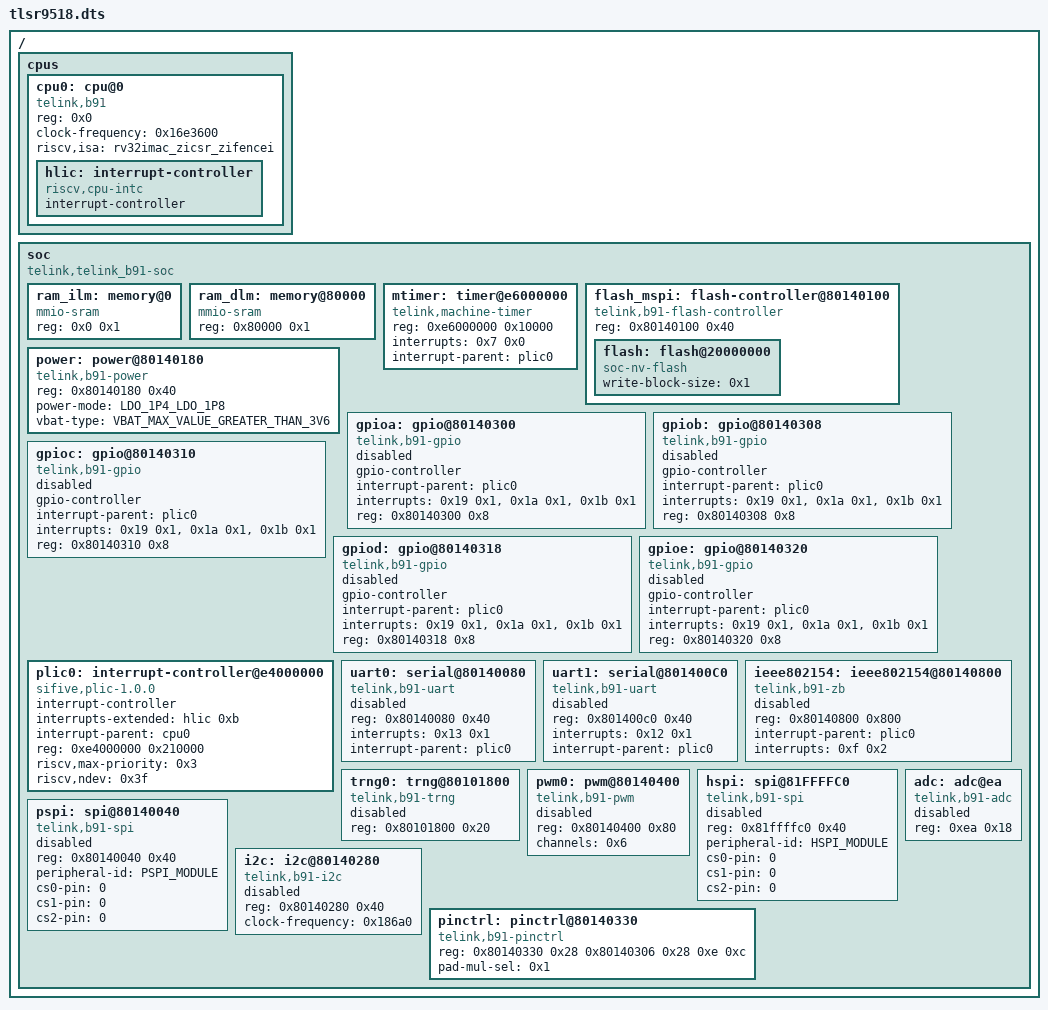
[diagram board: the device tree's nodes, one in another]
/dts-v1/;

/ {
	#address-cells = < 0x1 >;
	#size-cells = < 0x1 >;
	cpus {
		#address-cells = < 0x1 >;
		#size-cells = < 0x0 >;
		cpu0: cpu@0 {
			reg = < 0x0 >;
			clock-frequency = < 0x16e3600 >;
			compatible = "telink,b91", "riscv";
			riscv,isa = "rv32imac_zicsr_zifencei";
			phandle = < 0x3 >;
			hlic: interrupt-controller {
				compatible = "riscv,cpu-intc";
				#address-cells = < 0x0 >;
				#interrupt-cells = < 0x1 >;
				interrupt-controller;
				phandle = < 0x2 >;
			};
		};
	};
	soc {
		#address-cells = < 0x1 >;
		#size-cells = < 0x1 >;
		compatible = "telink,telink_b91-soc";
		ranges;
		ram_ilm: memory@0 {
			compatible = "mmio-sram";
			reg = < 0x0 0x1 >;
		};
		ram_dlm: memory@80000 {
			compatible = "mmio-sram";
			reg = < 0x80000 0x1 >;
		};
		mtimer: timer@e6000000 {
			compatible = "telink,machine-timer";
			reg = < 0xe6000000 0x10000 >;
			interrupts = < 0x7 0x0 >;
			interrupt-parent = < &plic0 >;
		};
		flash_mspi: flash-controller@80140100 {
			compatible = "telink,b91-flash-controller";
			reg = < 0x80140100 0x40 >;
			#address-cells = < 0x1 >;
			#size-cells = < 0x1 >;
			flash: flash@20000000 {
				compatible = "soc-nv-flash";
				write-block-size = < 0x1 >;
			};
		};
		power: power@80140180 {
			compatible = "telink,b91-power";
			reg = < 0x80140180 0x40 >;
			power-mode = "LDO_1P4_LDO_1P8";
			vbat-type = "VBAT_MAX_VALUE_GREATER_THAN_3V6";
			status = "okay";
		};
		gpioa: gpio@80140300 {
			compatible = "telink,b91-gpio";
			gpio-controller;
			interrupt-parent = < &plic0 >;
			interrupts = < 0x19 0x1 >, < 0x1a 0x1 >, < 0x1b 0x1 >;
			reg = < 0x80140300 0x8 >;
			status = "disabled";
			#gpio-cells = < 0x2 >;
		};
		gpiob: gpio@80140308 {
			compatible = "telink,b91-gpio";
			gpio-controller;
			interrupt-parent = < &plic0 >;
			interrupts = < 0x19 0x1 >, < 0x1a 0x1 >, < 0x1b 0x1 >;
			reg = < 0x80140308 0x8 >;
			status = "disabled";
			#gpio-cells = < 0x2 >;
		};
		gpioc: gpio@80140310 {
			compatible = "telink,b91-gpio";
			gpio-controller;
			interrupt-parent = < &plic0 >;
			interrupts = < 0x19 0x1 >, < 0x1a 0x1 >, < 0x1b 0x1 >;
			reg = < 0x80140310 0x8 >;
			status = "disabled";
			#gpio-cells = < 0x2 >;
		};
		gpiod: gpio@80140318 {
			compatible = "telink,b91-gpio";
			gpio-controller;
			interrupt-parent = < &plic0 >;
			interrupts = < 0x19 0x1 >, < 0x1a 0x1 >, < 0x1b 0x1 >;
			reg = < 0x80140318 0x8 >;
			status = "disabled";
			#gpio-cells = < 0x2 >;
		};
		gpioe: gpio@80140320 {
			compatible = "telink,b91-gpio";
			gpio-controller;
			interrupt-parent = < &plic0 >;
			interrupts = < 0x19 0x1 >, < 0x1a 0x1 >, < 0x1b 0x1 >;
			reg = < 0x80140320 0x8 >;
			status = "disabled";
			#gpio-cells = < 0x2 >;
		};
		plic0: interrupt-controller@e4000000 {
			compatible = "sifive,plic-1.0.0";
			#address-cells = < 0x0 >;
			#interrupt-cells = < 0x2 >;
			interrupt-controller;
			interrupts-extended = < &hlic 0xb >;
			interrupt-parent = < &cpu0 >;
			reg = < 0xe4000000 0x210000 >;
			riscv,max-priority = < 0x3 >;
			riscv,ndev = < 0x3f >;
			phandle = < 0x1 >;
		};
		uart0: serial@80140080 {
			compatible = "telink,b91-uart";
			reg = < 0x80140080 0x40 >;
			interrupts = < 0x13 0x1 >;
			interrupt-parent = < &plic0 >;
			status = "disabled";
		};
		uart1: serial@801400C0 {
			compatible = "telink,b91-uart";
			reg = < 0x801400c0 0x40 >;
			interrupts = < 0x12 0x1 >;
			interrupt-parent = < &plic0 >;
			status = "disabled";
		};
		ieee802154: ieee802154@80140800 {
			compatible = "telink,b91-zb";
			reg = < 0x80140800 0x800 >;
			interrupt-parent = < &plic0 >;
			interrupts = < 0xf 0x2 >;
			status = "disabled";
		};
		trng0: trng@80101800 {
			compatible = "telink,b91-trng";
			reg = < 0x80101800 0x20 >;
			status = "disabled";
		};
		pwm0: pwm@80140400 {
			compatible = "telink,b91-pwm";
			reg = < 0x80140400 0x80 >;
			channels = < 0x6 >;
			status = "disabled";
			#pwm-cells = < 0x3 >;
		};
		hspi: spi@81FFFFC0 {
			compatible = "telink,b91-spi";
			reg = < 0x81ffffc0 0x40 >;
			peripheral-id = "HSPI_MODULE";
			cs0-pin = "0";
			cs1-pin = "0";
			cs2-pin = "0";
			#address-cells = < 0x1 >;
			#size-cells = < 0x0 >;
			status = "disabled";
		};
		pspi: spi@80140040 {
			compatible = "telink,b91-spi";
			reg = < 0x80140040 0x40 >;
			peripheral-id = "PSPI_MODULE";
			cs0-pin = "0";
			cs1-pin = "0";
			cs2-pin = "0";
			#address-cells = < 0x1 >;
			#size-cells = < 0x0 >;
			status = "disabled";
		};
		i2c: i2c@80140280 {
			compatible = "telink,b91-i2c";
			reg = < 0x80140280 0x40 >;
			#address-cells = < 0x1 >;
			#size-cells = < 0x0 >;
			status = "disabled";
			clock-frequency = < 0x186a0 >;
		};
		adc: adc@ea {
			compatible = "telink,b91-adc";
			reg = < 0xea 0x18 >;
			status = "disabled";
			#io-channel-cells = < 0x1 >;
		};
		pinctrl: pinctrl@80140330 {
			compatible = "telink,b91-pinctrl";
			reg = < 0x80140330 0x28 0x80140306 0x28 0xe 0xc >;
			reg-names = "pin_mux", "gpio_en", "pull_up_en";
			status = "okay";
			pad-mul-sel = < 0x1 >;
		};
	};
};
